# PIC32MK0512MCF064 register map
Vendor: Microchip
Registers are 32-bit, read-write, reset 0x0 unless marked. A register's access mark holds for its fields unless they carry their own. Addresses are absolute, and some are shared; only a register's first bit layout is shown; [hi:lo] are bit positions.

## DMAC
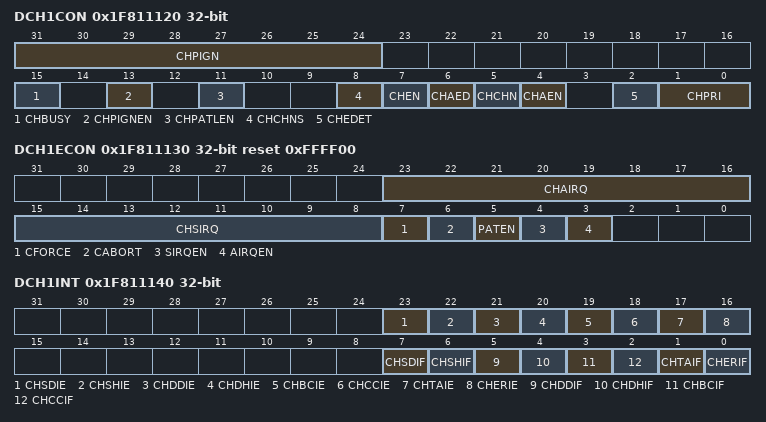
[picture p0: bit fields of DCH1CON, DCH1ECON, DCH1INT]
0x1F811120 DCH1CON reset not defined — (power-on value xxxxxxxx--------0-0-0--00000-000)
  [31:24] CHPIGN, [15] CHBUSY, [13] CHPIGNEN, [11] CHPATLEN, [8] CHCHNS, [7] CHEN, [6] CHAED, [5] CHCHN, [4] CHAEN, [2] CHEDET ro, [1:0] CHPRI
0x1F811130 DCH1ECON reset 0xFFFF00
  [23:16] CHAIRQ, [15:8] CHSIRQ, [7] CFORCE, [6] CABORT, [5] PATEN, [4] SIRQEN, [3] AIRQEN
0x1F811140 DCH1INT
  [23] CHSDIE, [22] CHSHIE, [21] CHDDIE, [20] CHDHIE, [19] CHBCIE, [18] CHCCIE, [17] CHTAIE, [16] CHERIE, [7] CHSDIF, [6] CHSHIF, [5] CHDDIF, [4] CHDHIF, [3] CHBCIF, [2] CHCCIF, [1] CHTAIF, [0] CHERIF
0x1F811150 DCH1SSA reset not defined — (power-on value xxxxxxxxxxxxxxxxxxxxxxxxxxxxxxxx)
  [31:0] CHSSA
0x1F811160 DCH1DSA reset not defined — (power-on value xxxxxxxxxxxxxxxxxxxxxxxxxxxxxxxx)
  [31:0] CHDSA
0x1F811170 DCH1SSIZ reset not defined — (power-on value ----------------xxxxxxxxxxxxxxxx)
  [15:0] CHSSIZ
0x1F811180 DCH1DSIZ reset not defined — (power-on value ----------------xxxxxxxxxxxxxxxx)
  [15:0] CHDSIZ
0x1F811190 DCH1SPTR
  [15:0] CHSPTR
0x1F8111A0 DCH1DPTR
  [15:0] CHDPTR
0x1F8111B0 DCH1CSIZ reset not defined — (power-on value ----------------xxxxxxxxxxxxxxxx)
  [15:0] CHCSIZ
0x1F8111C0 DCH1CPTR
  [15:0] CHCPTR
0x1F8111D0 DCH1DAT reset not defined — (power-on value ----------------xxxxxxxxxxxxxxxx)
  [15:0] CHPDAT

## TMR1
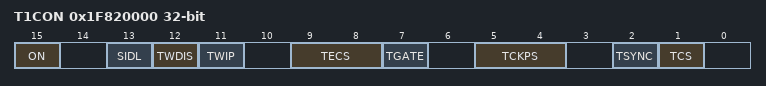
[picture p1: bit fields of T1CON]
0x1F820000 T1CON
  [15] ON, [13] SIDL, [12] TWDIS, [11] TWIP, [9:8] TECS, [7] TGATE, [5:4] TCKPS, [2] TSYNC, [1] TCS
0x1F820010 TMR1
0x1F820020 PR1 reset 0xFFFF

## TMR2
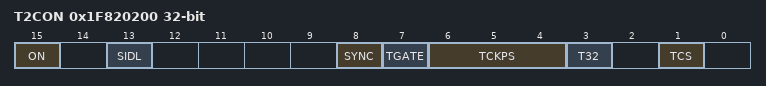
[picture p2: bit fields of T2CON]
0x1F820200 T2CON reset not defined — Timer Configuration (power-on value ----------------000----x00000-0-)
  [15] ON — Timer On bit
    1=Module is enabled; 0=Module is disabled
  [13] SIDL — Stop in Idle Mode bit
    1=Discontinue operation when device enters Idle mode; 0=Continue operation even in Idle mode
  [8] SYNC — Synchronized Timer Start/Stop Enable bit
    1=Synchronized timer Start/Stop is enabled; 0=Synchronized timer Start/Stop is disabled
  [7] TGATE — Timer Gated Time Accumulation Enable bit
    1=Gated time accumulation is enabled; 0=Gated time accumulation is disabled
  [6:4] TCKPS — Timer Input Clock Prescale Select bits
    7=1:256 prescale value; 6=1:64 prescale value; 5=1:32 prescale value; 4=1:16 prescale value; 3=1:8 prescale value; 2=1:4 prescale value; 1=1:2 prescale value; 0=1:1 prescale value
  [3] T32 — 32-Bit Timer Mode Select bit
    1=32-bit Timer mode; 0=16-bit Timer mode
  [1] TCS — Timer Clock Source Select bit
    1=External clock from TxCK pin; 0=Internal peripheral clock
0x1F820210 TMR2 — Timer
0x1F820220 PR2 reset 0xFFFFFFFF — Timer Period

## TMR3
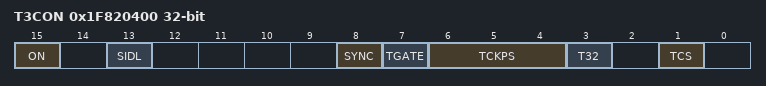
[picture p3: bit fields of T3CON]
0x1F820400 T3CON reset not defined — Timer Configuration (power-on value ----------------000----x00000-0-)
  [15] ON — Timer On bit
    1=Module is enabled; 0=Module is disabled
  [13] SIDL — Stop in Idle Mode bit
    1=Discontinue operation when device enters Idle mode; 0=Continue operation even in Idle mode
  [8] SYNC — Synchronized Timer Start/Stop Enable bit
    1=Synchronized timer Start/Stop is enabled; 0=Synchronized timer Start/Stop is disabled
  [7] TGATE — Timer Gated Time Accumulation Enable bit
    1=Gated time accumulation is enabled; 0=Gated time accumulation is disabled
  [6:4] TCKPS — Timer Input Clock Prescale Select bits
    7=1:256 prescale value; 6=1:64 prescale value; 5=1:32 prescale value; 4=1:16 prescale value; 3=1:8 prescale value; 2=1:4 prescale value; 1=1:2 prescale value; 0=1:1 prescale value
  [3] T32 — 32-Bit Timer Mode Select bit
    1=32-bit Timer mode; 0=16-bit Timer mode
  [1] TCS — Timer Clock Source Select bit
    1=External clock from TxCK pin; 0=Internal peripheral clock
0x1F820410 TMR3 — Timer
0x1F820420 PR3 reset 0xFFFFFFFF — Timer Period
